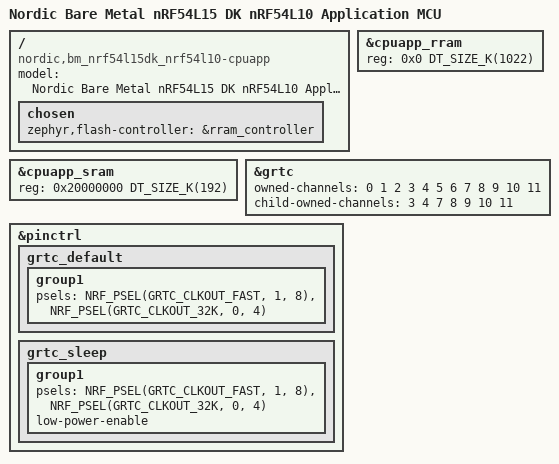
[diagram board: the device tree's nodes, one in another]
/*
 * Copyright (c) 2025 Nordic Semiconductor ASA
 *
 * SPDX-License-Identifier: Apache-2.0
 */

/ {
	compatible = "nordic,bm_nrf54l15dk_nrf54l10-cpuapp";
	model = "Nordic Bare Metal nRF54L15 DK nRF54L10 Application MCU";

	chosen {
		zephyr,flash-controller = &rram_controller;
	};
};

/* Override NCS default to use entire SRAM for application CPU. */
&cpuapp_sram {
	reg = <0x20000000 DT_SIZE_K(192)>;
	ranges = <0x0 0x20000000 DT_SIZE_K(192)>;
};

/* Override NCS default to use entire RRAM for application CPU. */
&cpuapp_rram {
	reg = <0x0 DT_SIZE_K(1022)>;
};

&grtc {
	owned-channels = <0 1 2 3 4 5 6 7 8 9 10 11>;
	/* Channels 7-11 reserved for Zero Latency IRQs, 3-4 for FLPR */
	child-owned-channels = <3 4 7 8 9 10 11>;
	status = "okay";
};

&pinctrl {
	/omit-if-no-ref/ grtc_default: grtc_default {
		group1 {
			psels = <NRF_PSEL(GRTC_CLKOUT_FAST, 1, 8)>,
				<NRF_PSEL(GRTC_CLKOUT_32K, 0, 4)>;
		};
	};

	/omit-if-no-ref/ grtc_sleep: grtc_sleep {
		group1 {
			psels = <NRF_PSEL(GRTC_CLKOUT_FAST, 1, 8)>,
				<NRF_PSEL(GRTC_CLKOUT_32K, 0, 4)>;
			low-power-enable;
		};
	};
};
